# STM32H573 register map
File version: 0.4
CPU: CM33 r0p0, little endian, MPU, FPU, 4 interrupt priority bits
Registers are 32-bit, read-write, reset 0x0 unless marked. A register's access mark holds for its fields unless they carry their own. Offsets are from the block's base; [hi:lo] are bit positions.

## FDCAN1 — Controller area network
Base 0x4000A400
Same registers: FDCAN2 0x4000A800, SEC_FDCAN1 0x5000A400, SEC_FDCAN2 0x5000A800
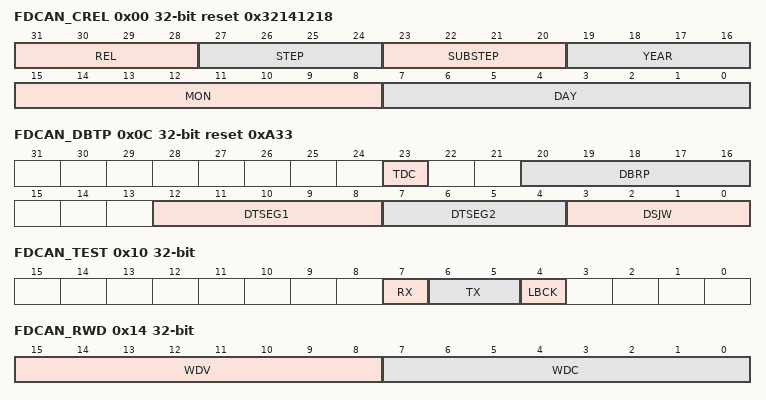
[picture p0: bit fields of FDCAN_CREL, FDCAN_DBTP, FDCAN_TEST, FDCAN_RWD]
0x00 FDCAN_CREL ro reset 0x32141218 — FDCAN core release register
  [31:28] REL — 3
  [27:24] STEP — 2
  [23:20] SUBSTEP — 1
  [19:16] YEAR — 4
  [15:8] MON — 12
  [7:0] DAY — 18
0x04 FDCAN_ENDN ro reset 0x87654321 — FDCAN endian register
  [31:0] ETV — Endianness test value The endianness test value is 0x8765 4321.
0x0C FDCAN_DBTP reset 0xA33 — FDCAN data bit timing and prescaler register
  [23] TDC — Transceiver delay compensation
  [20:16] DBRP — Data bit rate prescaler The value by which the oscillator frequency is divided to generate the bit time quanta. The bit time is built up from a multiple of this quanta. Valid values for the Baud Rate Prescaler are 0 to 31. The hardware interpreters this value as the value programmed plus 1.
  [12:8] DTSEG1 — Data time segment before sample point Valid values are 0 to 31. The value used by the hardware is the one programmed, incremented by 1, i.e. tBS1 = (DTSEG1 + 1) x tq.
  [7:4] DTSEG2 — Data time segment after sample point Valid values are 0 to 15. The value used by the hardware is the one programmed, incremented by 1, i.e. tBS2 = (DTSEG2 + 1) x tq.
  [3:0] DSJW — Synchronization jump width Must always be smaller than DTSEG2, valid values are 0 to 15. The value used by the hardware is the one programmed, incremented by 1: tSJW = (DSJW + 1) x tq.
0x10 FDCAN_TEST access per field
  [7] RX ro — Receive pin Monitors the actual value of pin FDCANx_RX
  [6:5] TX rw — Control of transmit pin
  [4] LBCK rw — Loop back mode
0x14 FDCAN_RWD access per field — FDCAN RAM watchdog register
  [15:8] WDV ro — Watchdog value Actual message RAM watchdog counter value.
  [7:0] WDC rw — Watchdog configuration Start value of the message RAM watchdog counter. With the reset value of 00, the counter is disabled. These are protected write (P) bits, write access is possible only when the bit 1 [CCE] and bit 0 [INIT] of FDCAN_CCCR register are set to 1.
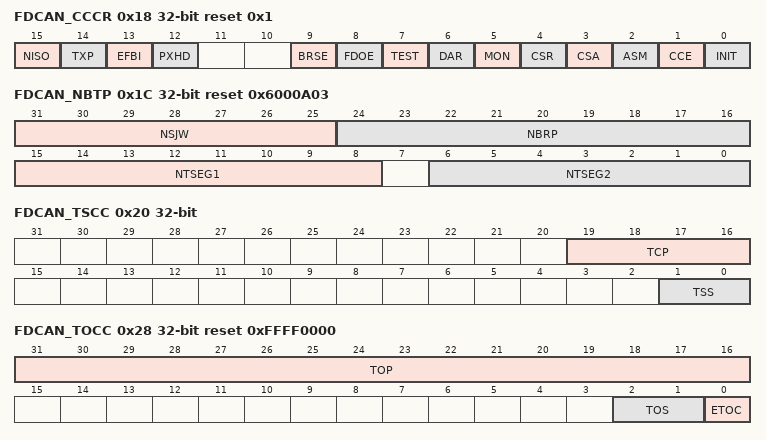
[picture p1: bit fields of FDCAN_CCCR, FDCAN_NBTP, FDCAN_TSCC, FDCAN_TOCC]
0x18 FDCAN_CCCR access per field reset 0x1 — FDCAN CC control register
  [15] NISO rw — Non ISO operation If this bit is set, the FDCAN uses the CAN FD frame format as specified by the Bosch CAN FD Specification V1.0.
  [14] TXP rw — If this bit is set, the FDCAN pauses for two CAN bit times before starting the next transmission after successfully transmitting a frame.
  [13] EFBI rw — Edge filtering during bus integration
  [12] PXHD rw — Protocol exception handling disable
  [9] BRSE rw — FDCAN bit rate switching
  [8] FDOE rw — FD operation enable
  [7] TEST rw — Test mode enable
  [6] DAR rw — Disable automatic retransmission
  [5] MON rw — Bus monitoring mode Bit MON can only be set by software when both CCE and INIT are set to 1. The bit can be reset by the Host at any time.
  [4] CSR rw — Clock stop request
  [3] CSA ro — Clock stop acknowledge
  [2] ASM rw — ASM restricted operation mode The restricted operation mode is intended for applications that adapt themselves to different CAN bit rates. The application tests different bit rates and leaves the Restricted operation Mode after it has received a valid frame. In the optional Restricted operation Mode the node is able to transmit and receive data and remote frames and it gives acknowledge to valid frames, but it does not send active error frames or overload frames. In case of an error condition or overload condition, it does not send dominant bits, instead it waits for the occurrence of bus idle condition to resynchronize itself to the CAN communication. The error counters are not incremented. Bit ASM can only be set by software when both CCE and INIT are set to 1. The bit can be reset by the software at any time.
  [1] CCE rw — Configuration change enable
  [0] INIT rw — Initialization
0x1C FDCAN_NBTP reset 0x6000A03 — FDCAN nominal bit timing and prescaler register
  [31:25] NSJW — Nominal (re)synchronization jump width Valid values are 0 to 127. The actual interpretation by the hardware of this value is such that the used value is the one programmed incremented by one. These are protected write (P) bits, write access is possible only when the bit 1 [CCE] and bit 0 [INIT] of CCCR register are set to 1.
  [24:16] NBRP — Bit rate prescaler Value by which the oscillator frequency is divided for generating the bit time quanta. The bit time is built up from a multiple of this quanta. Valid values are 0 to 511. The actual interpretation by the hardware of this value is such that one more than the value programmed here is used. These are protected write (P) bits, write access is possible only when the bit 1 [CCE] and bit 0 [INIT] of CCCR register are set to 1.
  [15:8] NTSEG1 — Nominal time segment before sample point Valid values are 0 to 255. The actual interpretation by the hardware of this value is such that one more than the programmed value is used. These are protected write (P) bits, write access is possible only when the bit 1 [CCE] and bit 0 [INIT] of CCCR register are set to 1.
  [6:0] NTSEG2 — Nominal time segment after sample point Valid values are 0 to 127. The actual interpretation by the hardware of this value is such that one more than the programmed value is used.
0x20 FDCAN_TSCC — FDCAN timestamp counter configuration register
  [19:16] TCP — Timestamp counter prescaler Configures the timestamp and timeout counters time unit in multiples of CAN bit times [1 … 16]. The actual interpretation by the hardware of this value is such that one more than the value programmed here is used. In CAN FD mode the internal timestamp counter TCP does not provide a constant time base due to the different CAN bit times between arbitration phase and data phase. Thus CAN FD requires an external counter for timestamp generation (TSS = 10). These are protected write (P) bits, write access is possible only when the bit 1 [CCE] and bit 0 [INIT] of CCCR register are set to 1.
  [1:0] TSS — Timestamp select These are protected write (P) bits, write access is possible only when the bit 1 [CCE] and bit 0 [INIT] of CCCR register are set to 1.
0x24 FDCAN_TSCV — FDCAN timestamp counter value register
  [15:0] TSC — Timestamp counter The internal/external timestamp counter value is captured on start of frame (both Rx and Tx). When TSCC[TSS] = 01, the timestamp counter is incremented in multiples of CAN bit times [1 … 16] depending on the configuration of TSCC[TCP]. A wrap around sets interrupt flag IR[TSW]. Write access resets the counter to 0. When TSCC.TSS = 10, TSC reflects the external timestamp counter value. A write access has no impact.
0x28 FDCAN_TOCC reset 0xFFFF0000 — FDCAN timeout counter configuration register
  [31:16] TOP — Timeout period Start value of the timeout counter (down-counter). Configures the timeout period.
  [2:1] TOS — Timeout select When operating in Continuous mode, a write to TOCV presets the counter to the value configured by TOCC[TOP] and continues down-counting. When the timeout counter is controlled by one of the FIFOs, an empty FIFO presets the counter to the value configured by TOCC[TOP]. Down-counting is started when the first FIFO element is stored. These are protected write (P) bits, write access is possible only when the bit 1 [CCE] and bit 0 [INIT] of CCCR register are set to 1.
  [0] ETOC — Timeout counter enable This is a protected write (P) bit, write access is possible only when the bit 1 [CCE] and bit 0 [INIT] of CCCR register are set to 1.
0x2C FDCAN_TOCV reset 0xFFFF — FDCAN timeout counter value register
  [15:0] TOC — Timeout counter The timeout counter is decremented in multiples of CAN bit times [1 … 16] depending on the configuration of TSCC.TCP. When decremented to 0, interrupt flag IR.TOO is set and the timeout counter is stopped. Start and reset/restart conditions are configured via TOCC.TOS.
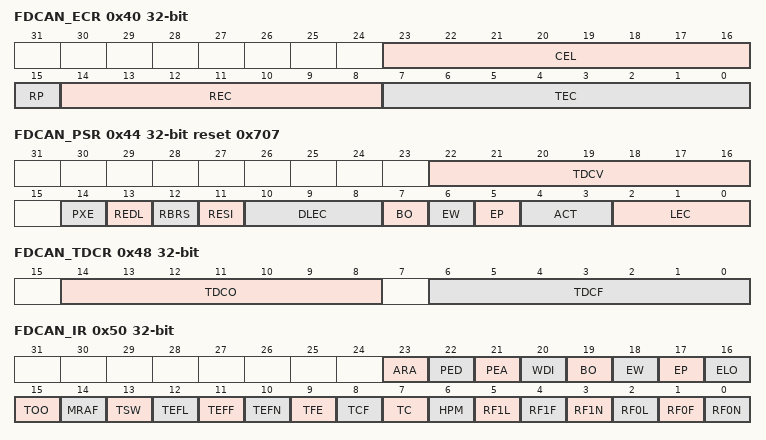
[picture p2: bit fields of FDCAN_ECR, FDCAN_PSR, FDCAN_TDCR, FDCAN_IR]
0x40 FDCAN_ECR access per field — FDCAN error counter register
  [23:16] CEL rw — CAN error logging The counter is incremented each time when a CAN protocol error causes the transmit error counter or the receive error counter to be incremented. It is reset by read access to CEL. The counter stops at 0xFF; the next increment of TEC or REC sets interrupt flag IR[ELO]. Access type is RX: reset on read.
  [15] RP ro — Receive error passive
  [14:8] REC ro — Receive error counter Actual state of the receive error counter, values between 0 and 127.
  [7:0] TEC ro — Transmit error counter Actual state of the transmit error counter, values between 0 and 255. When CCCR.ASM is set, the CAN protocol controller does not increment TEC and REC when a CAN protocol error is detected, but CEL is still incremented.
0x44 FDCAN_PSR access per field reset 0x707 — FDCAN protocol status register
  [22:16] TDCV ro — Transmitter delay compensation value Position of the secondary sample point, defined by the sum of the measured delay from FDCAN_TX to FDCAN_RX and TDCR.TDCO. The SSP position is, in the data phase, the number of minimum time quanta (mtq) between the start of the transmitted bit and the secondary sample point. Valid values are 0 to 127 mtq.
  [14] PXE rw — Protocol exception event
  [13] REDL rw — Received FDCAN message This bit is set independent of acceptance filtering. Access type is RX: reset on read.
  [12] RBRS rw — BRS flag of last received FDCAN message This bit is set together with REDL, independent of acceptance filtering. Access type is RX: reset on read.
  [11] RESI rw — ESI flag of last received FDCAN message This bit is set together with REDL, independent of acceptance filtering. Access type is RX: reset on read.
  [10:8] DLEC rw — Data last error code Type of last error that occurred in the data phase of a FDCAN format frame with its BRS flag set. Coding is the same as for LEC. This field is cleared to 0 when a FDCAN format frame with its BRS flag set has been transferred (reception or transmission) without error. Access type is RS: set on read.
  [7] BO ro — Bus_Off status
  [6] EW ro — Warning Sstatus
  [5] EP ro — Error passive
  [4:3] ACT ro — Activity Monitors the module’s CAN communication state.
  [2:0] LEC rw — Last error code The LEC indicates the type of the last error to occur on the CAN bus. This field is cleared to 0 when a message has been transferred (reception or transmission) without error. Access type is RS: set on read.
0x48 FDCAN_TDCR — FDCAN transmitter delay compensation register
  [14:8] TDCO — Transmitter delay compensation offset Offset value defining the distance between the measured delay from FDCAN_TX to FDCAN_RX and the secondary sample point. Valid values are 0 to 127 mtq. These are protected write (P) bits, which means that write access by the bits is possible only when the bit 1 [CCE] and bit 0 [INIT] of CCCR register are set to 1.
  [6:0] TDCF — Transmitter delay compensation filter window length Defines the minimum value for the SSP position, dominant edges on FDCAN_RX that would result in an earlier SSP position are ignored for transmitter delay measurements. These are protected write (P) bits, which means that write access by the bits is possible only when the bit 1 [CCE] and bit 0 [INIT] of CCCR register are set to 1.
0x50 FDCAN_IR — FDCAN interrupt register
  [23] ARA — Access to reserved address
  [22] PED — Protocol error in data phase (data bit time is used)
  [21] PEA — Protocol error in arbitration phase (nominal bit time is used)
  [20] WDI — Watchdog interrupt
  [19] BO — Bus_Off status
  [18] EW — Warning status
  [17] EP — Error passive
  [16] ELO — Error logging overflow
  [15] TOO — Timeout occurred
  [14] MRAF — Message RAM access failure The flag is set when the Rx handler: has not completed acceptance filtering or storage of an accepted message until the arbitration field of the following message has been received. In this case acceptance filtering or message storage is aborted and the Rx handler starts processing of the following message. was unable to write a message to the message RAM. In this case message storage is aborted. In both cases the FIFO put index is not updated. The partly stored message is overwritten when the next message is stored to this location. The flag is also set when the Tx Handler was not able to read a message from the Message RAM in time. In this case message transmission is aborted. In case of a Tx Handler access failure the FDCAN is switched into Restricted operation Mode (see mode). To leave Restricted operation Mode, the Host CPU has to reset CCCR.ASM.
  [13] TSW — Timestamp wraparound
  [12] TEFL — Tx event FIFO element lost
  [11] TEFF — Tx event FIFO full
  [10] TEFN — Tx event FIFO New Entry
  [9] TFE — Tx FIFO empty
  [8] TCF — Transmission cancellation finished
  [7] TC — Transmission completed
  [6] HPM — High-priority message
  [5] RF1L — Rx FIFO 1 message lost
  [4] RF1F — Rx FIFO 1 full
  [3] RF1N — Rx FIFO 1 new message
  [2] RF0L — Rx FIFO 0 message lost
  [1] RF0F — Rx FIFO 0 full
  [0] RF0N — Rx FIFO 0 new message
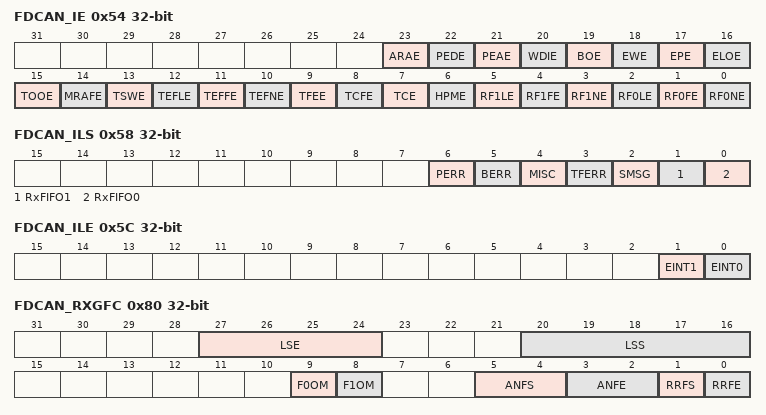
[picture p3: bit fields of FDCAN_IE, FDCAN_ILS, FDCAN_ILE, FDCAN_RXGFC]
0x54 FDCAN_IE — FDCAN interrupt enable register
  [23] ARAE — Access to reserved address enable
  [22] PEDE — Protocol error in data phase enable
  [21] PEAE — Protocol error in arbitration phase enable
  [20] WDIE — Watchdog interrupt enable
  [19] BOE — Bus_Off status
  [18] EWE — Warning status interrupt enable
  [17] EPE — Error passive interrupt enable
  [16] ELOE — Error logging overflow interrupt enable
  [15] TOOE — Timeout occurred interrupt enable
  [14] MRAFE — Message RAM access failure interrupt enable
  [13] TSWE — Timestamp wraparound interrupt enable
  [12] TEFLE — Tx event FIFO element lost interrupt enable
  [11] TEFFE — Tx event FIFO full interrupt enable
  [10] TEFNE — Tx event FIFO new entry interrupt enable
  [9] TFEE — Tx FIFO empty interrupt enable
  [8] TCFE — Transmission cancellation finished interrupt enable
  [7] TCE — Transmission completed interrupt enable
  [6] HPME — High-priority message interrupt enable
  [5] RF1LE — Rx FIFO 1 message lost interrupt enable
  [4] RF1FE — Rx FIFO 1 full interrupt enable
  [3] RF1NE — Rx FIFO 1 new message interrupt enable
  [2] RF0LE — Rx FIFO 0 message lost interrupt enable
  [1] RF0FE — Rx FIFO 0 full interrupt enable
  [0] RF0NE — Rx FIFO 0 new message interrupt enable
0x58 FDCAN_ILS — FDCAN interrupt line select register
  [6] PERR — Protocol error grouping the following interruption ARAL: Access to reserved address line PEDL: Protocol error in data phase line PEAL: Protocol error in arbitration phase line WDIL: Watchdog interrupt line BOL: Bus_Off status EWL: Warning status interrupt line
  [5] BERR — Bit and line error grouping the following interruption EPL Error passive interrupt line ELOL: Error logging overflow interrupt line
  [4] MISC — Interrupt regrouping the following interruption TOOL: Timeout occurred interrupt line MRAFL: Message RAM access failure interrupt line TSWL: Timestamp wraparound interrupt line
  [3] TFERR — Tx FIFO ERROR grouping the following interruption TEFLL: Tx event FIFO element lost interrupt line TEFFL: Tx event FIFO full interrupt line TEFNL: Tx event FIFO new entry interrupt line TFEL: Tx FIFO empty interrupt line
  [2] SMSG — Status message bit grouping the following interruption TCFL: Transmission cancellation finished interrupt line TCL: Transmission completed interrupt line HPML: High-priority message interrupt line
  [1] RxFIFO1 — RX FIFO bit grouping the following interruption RF1LL: Rx FIFO 1 message lost interrupt line RF1FL: Rx FIFO 1 full Interrupt line RF1NL: Rx FIFO 1 new message interrupt line
  [0] RxFIFO0 — RX FIFO bit grouping the following interruption RF0LL: Rx FIFO 0 message lost interrupt line RF0FL: Rx FIFO 0 full interrupt line RF0NL: Rx FIFO 0 new message interrupt line
0x5C FDCAN_ILE — FDCAN interrupt line enable register
  [1] EINT1 — Enable interrupt line 1
  [0] EINT0 — Enable interrupt line 0
0x80 FDCAN_RXGFC — FDCAN global filter configuration register
  [27:24] LSE — List size extended >8: Values greater than 8 are interpreted as 8. These are protected write (P) bits, which means that write access by the bits is possible only when the bit 1 [CCE] and bit 0 [INIT] of CCCR register are set to 1.
  [20:16] LSS — List size standard >28: Values greater than 28 are interpreted as 28. These are protected write (P) bits, which means that write access by the bits is possible only when the bit 1 [CCE] and bit 0 [INIT] of CCCR register are set to 1.
  [9] F0OM — FIFO 0 operation mode (overwrite or blocking) This is protected write (P) bits, which means that write access by the bits is possible only when the bit 1 [CCE] and bit 0 [INIT] of CCCR register are set to 1.
  [8] F1OM — FIFO 1 operation mode (overwrite or blocking) This is a protected write (P) bits, which means that write access by the bits is possible only when the bit 1 [CCE] and bit 0 [INIT] of CCCR register are set to 1.
  [5:4] ANFS — Accept Non-matching frames standard Defines how received messages with 11-bit IDs that do not match any element of the filter list are treated. These are protected write (P) bits, which means that write access by the bits is possible only when the bit 1 [CCE] and bit 0 [INIT] of CCCR register are set to 1.
  [3:2] ANFE — Accept non-matching frames extended Defines how received messages with 29-bit IDs that do not match any element of the filter list are treated. These are protected write (P) bits, which means that write access by the bits is possible only when the bit 1 [CCE] and bit 0 [INIT] of CCCR register are set to 1.
  [1] RRFS — Reject remote frames standard These are protected write (P) bits, which means that write access by the bits is possible only when the bit 1 [CCE] and bit 0 [INIT] of CCCR register are set to 1.
  [0] RRFE — Reject remote frames extended These are protected write (P) bits, which means that write access by the bits is possible only when the bit 1 [CCE] and bit 0 [INIT] of CCCR register are set to 1.
0x84 FDCAN_XIDAM reset 0x1FFFFFFF — FDCAN extended ID and mask register
  [28:0] EIDM — Extended ID mask For acceptance filtering of extended frames the Extended ID AND Mask is AND-ed with the Message ID of a received frame. Intended for masking of 29-bit IDs in SAE J1939. With the reset value of all bits set to 1 the mask is not active. These are protected write (P) bits, which means that write access by the bits is possible only when the bit 1 [CCE] and bit 0 [INIT] of CCCR register are set to 1.
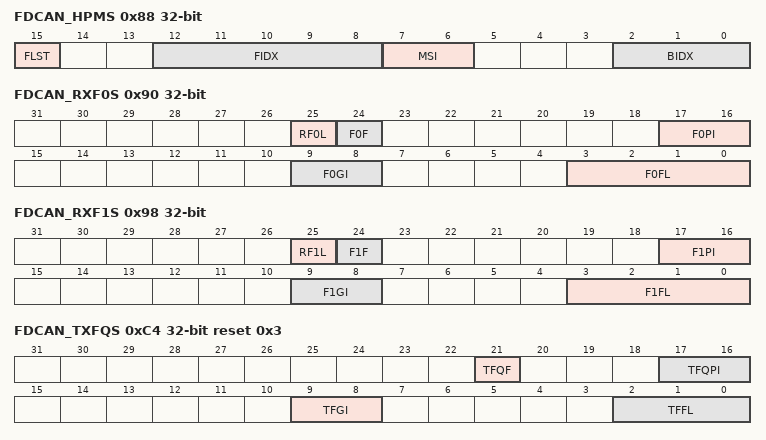
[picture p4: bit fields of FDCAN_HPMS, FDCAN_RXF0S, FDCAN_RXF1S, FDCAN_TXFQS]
0x88 FDCAN_HPMS ro — FDCAN high-priority message status register
  [15] FLST — Filter list Indicates the filter list of the matching filter element.
  [12:8] FIDX — Filter index Index of matching filter element. Range is 0 to RXGFC[LSS] - 1 or RXGFC[LSE] - 1.
  [7:6] MSI — Message storage indicator
  [2:0] BIDX — Buffer index Index of Rx FIFO element to which the message was stored. Only valid when MSI[1] = 1.
0x90 FDCAN_RXF0S ro — FDCAN Rx FIFO 0 status register
  [25] RF0L — Rx FIFO 0 message lost This bit is a copy of interrupt flag IR[RF0L]. When IR[RF0L] is reset, this bit is also reset.
  [24] F0F — Rx FIFO 0 full
  [17:16] F0PI — Rx FIFO 0 put index Rx FIFO 0 write index pointer, range 0 to 2.
  [9:8] F0GI — Rx FIFO 0 get index Rx FIFO 0 read index pointer, range 0 to 2.
  [3:0] F0FL — Rx FIFO 0 fill level Number of elements stored in Rx FIFO 0, range 0 to 3.
0x94 FDCAN_RXF0A — CAN Rx FIFO 0 acknowledge register
  [2:0] F0AI — Rx FIFO 0 acknowledge index After the Host has read a message or a sequence of messages from Rx FIFO 0 it has to write the buffer index of the last element read from Rx FIFO 0 to F0AI. This sets the Rx FIFO 0 get index RXF0S[F0GI] to F0AI + 1 and update the FIFO 0 fill level RXF0S[F0FL].
0x98 FDCAN_RXF1S ro — FDCAN Rx FIFO 1 status register
  [25] RF1L — Rx FIFO 1 message lost This bit is a copy of interrupt flag IR[RF1L]. When IR[RF1L] is reset, this bit is also reset.
  [24] F1F — Rx FIFO 1 full
  [17:16] F1PI — Rx FIFO 1 put index Rx FIFO 1 write index pointer, range 0 to 2.
  [9:8] F1GI — Rx FIFO 1 get index Rx FIFO 1 read index pointer, range 0 to 2.
  [3:0] F1FL — Rx FIFO 1 fill level Number of elements stored in Rx FIFO 1, range 0 to 3.
0x9C FDCAN_RXF1A — FDCAN Rx FIFO 1 acknowledge register
  [2:0] F1AI — Rx FIFO 1 acknowledge index After the Host has read a message or a sequence of messages from Rx FIFO 1 it has to write the buffer index of the last element read from Rx FIFO 1 to F1AI. This sets the Rx FIFO 1 get index RXF1S[F1GI] to F1AI + 1 and update the FIFO 1 Fill Level RXF1S[F1FL].
0xC0 FDCAN_TXBC — FDCAN Tx buffer configuration register
  [24] TFQM — Tx FIFO/queue mode This is a protected write (P) bit, which means that write access by the bits is possible only when the bit 1 [CCE] and bit 0 [INIT] of CCCR register are set to 1.
0xC4 FDCAN_TXFQS ro reset 0x3 — FDCAN Tx FIFO/queue status register
  [21] TFQF — Tx FIFO/queue full
  [17:16] TFQPI — Tx FIFO/queue put index Tx FIFO/queue write index pointer, range 0 to 3
  [9:8] TFGI — Tx FIFO get index Tx FIFO read index pointer, range 0 to 3. Read as 0 when Tx queue operation is configured (TXBC.TFQM = 1)
  [2:0] TFFL — Tx FIFO free level Number of consecutive free Tx FIFO elements starting from TFGI, range 0 to 3. Read as 0 when Tx queue operation is configured (TXBC[TFQM] = 1).
0xC8 FDCAN_TXBRP ro — FDCAN Tx buffer request pending register
  [2:0] TRP — Transmission request pending Each Tx buffer has its own transmission request pending bit. The bits are set via register TXBAR. The bits are reset after a requested transmission has completed or has been canceled via register TXBCR. After a TXBRP bit has been set, a Tx scan is started to check for the pending Tx request with the highest priority (Tx buffer with lowest Message ID). A cancellation request resets the corresponding transmission request pending bit of register TXBRP. In case a transmission has already been started when a cancellation is requested, this is done at the end of the transmission, regardless whether the transmission was successful or not. The cancellation request bits are reset directly after the corresponding TXBRP bit has been reset. After a cancellation has been requested, a finished cancellation is signaled via TXBCF after successful transmission together with the corresponding TXBTO bit when the transmission has not yet been started at the point of cancellation when the transmission has been aborted due to lost arbitration when an error occurred during frame transmission In DAR mode all transmissions are automatically canceled if they are not successful. The corresponding TXBCF bit is set for all unsuccessful transmissions.
0xCC FDCAN_TXBAR — FDCAN Tx buffer add request register
  [2:0] AR — Add request Each Tx buffer has its own add request bit. Writing a 1 sets the corresponding add request bit; writing a 0 has no impact. This enables the Host to set transmission requests for multiple Tx buffers with one write to TXBAR. When no Tx scan is running, the bits are reset immediately, else the bits remain set until the Tx scan process has completed.
0xD0 FDCAN_TXBCR — FDCAN Tx buffer cancellation request register
  [2:0] CR — Cancellation request Each Tx buffer has its own cancellation request bit. Writing a 1 sets the corresponding CR bit; writing a 0 has no impact. This enables the Host to set cancellation requests for multiple Tx buffers with one write to TXBCR. The bits remain set until the corresponding TXBRP bit is reset.
0xD4 FDCAN_TXBTO ro — FDCAN Tx buffer transmission occurred register
  [2:0] TO — Transmission occurred. Each Tx buffer has its own TO bit. The bits are set when the corresponding TXBRP bit is cleared after a successful transmission. The bits are reset when a new transmission is requested by writing a 1 to the corresponding bit of register TXBAR.
0xD8 FDCAN_TXBCF ro — FDCAN Tx buffer cancellation finished register
  [2:0] CF — Cancellation finished Each Tx buffer has its own CF bit. The bits are set when the corresponding TXBRP bit is cleared after a cancellation was requested via TXBCR. In case the corresponding TXBRP bit was not set at the point of cancellation, CF is set immediately. The bits are reset when a new transmission is requested by writing a 1 to the corresponding bit of register TXBAR.
0xDC FDCAN_TXBTIE — FDCAN Tx buffer transmission interrupt enable register
  [2:0] TIE — Transmission interrupt enable Each Tx buffer has its own TIE bit.
0xE0 FDCAN_TXBCIE — FDCAN Tx buffer cancellation finished interrupt enable register
  [2:0] CFIE — Cancellation finished interrupt enable. Each Tx buffer has its own CFIE bit.
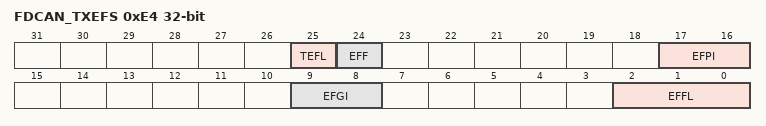
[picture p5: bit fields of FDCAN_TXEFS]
0xE4 FDCAN_TXEFS ro — FDCAN Tx event FIFO status register
  [25] TEFL — Tx event FIFO element lost This bit is a copy of interrupt flag IR[TEFL]. When IR[TEFL] is reset, this bit is also reset. 0 No Tx event FIFO element lost 1 Tx event FIFO element lost, also set after write attempt to Tx event FIFO of size 0.
  [24] EFF — Event FIFO full
  [17:16] EFPI — Event FIFO put index Tx event FIFO write index pointer, range 0 to 3.
  [9:8] EFGI — Event FIFO get index Tx event FIFO read index pointer, range 0 to 3.
  [2:0] EFFL — Event FIFO fill level Number of elements stored in Tx event FIFO, range 0 to 3.
0xE8 FDCAN_TXEFA — FDCAN Tx event FIFO acknowledge register
  [1:0] EFAI — Event FIFO acknowledge index After the Host has read an element or a sequence of elements from the Tx event FIFO, it has to write the index of the last element read from Tx event FIFO to EFAI. This sets the Tx event FIFO get index TXEFS[EFGI] to EFAI + 1 and updates the FIFO 0 fill level TXEFS[EFFL].
0x100 FDCAN_CKDIV — FDCAN CFG clock divider register
  [3:0] PDIV — input clock divider The APB clock could be divided prior to be used by the CAN sub system. The rate must be computed using the divider output clock. These are protected write (P) bits, which means that write access by the bits is possible only when the bit 1 [CCE] and bit 0 [INIT] of CCCR register are set to 1.
